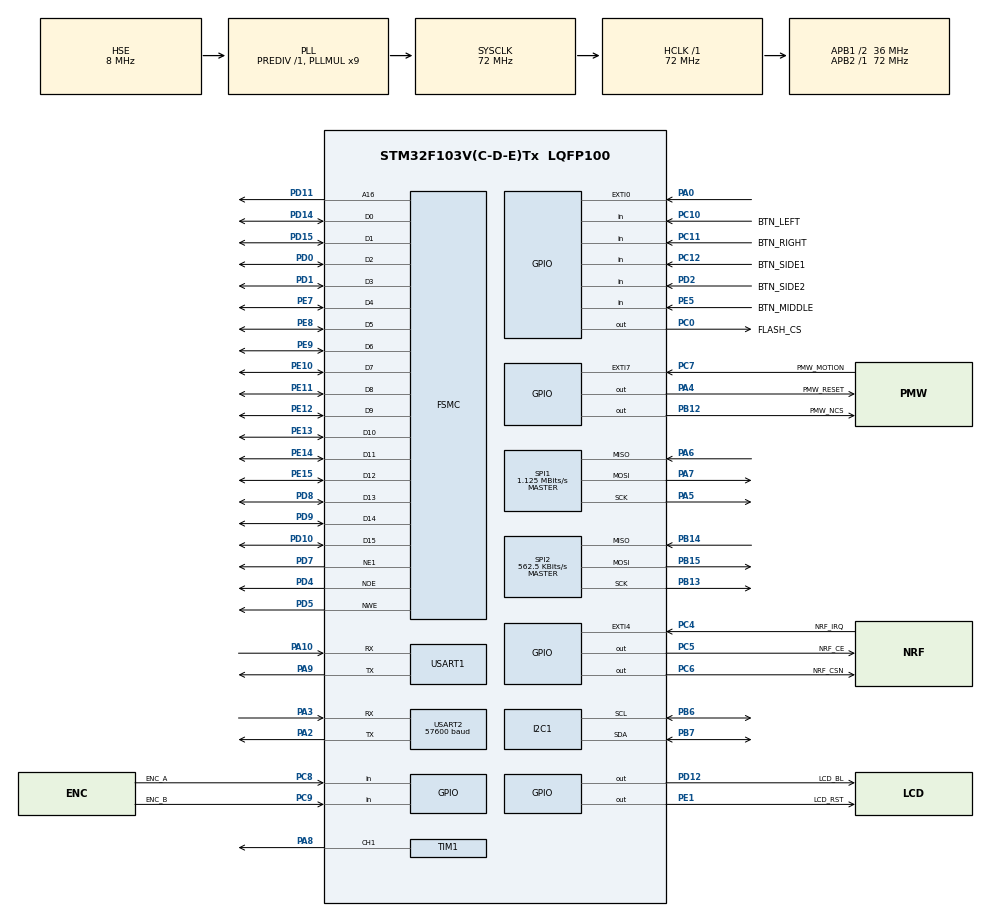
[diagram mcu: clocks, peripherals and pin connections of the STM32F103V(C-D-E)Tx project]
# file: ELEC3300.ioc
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Dma.Request0=TIM1_CH1
Dma.TIM1_CH1.0.Direction=DMA_MEMORY_TO_PERIPH
Dma.TIM1_CH1.0.Instance=DMA1_Channel2
Dma.TIM1_CH1.0.MemDataAlignment=DMA_MDATAALIGN_HALFWORD
Dma.TIM1_CH1.0.MemInc=DMA_MINC_ENABLE
Dma.TIM1_CH1.0.Mode=DMA_NORMAL
Dma.TIM1_CH1.0.PeriphDataAlignment=DMA_PDATAALIGN_HALFWORD
Dma.TIM1_CH1.0.PeriphInc=DMA_PINC_DISABLE
Dma.TIM1_CH1.0.Priority=DMA_PRIORITY_HIGH
FREERTOS.Tasks01=defaultTask,24,256,StartDefaultTask,Default,NULL,Dynamic,NULL,NULL
FREERTOS.configTOTAL_HEAP_SIZE=16384
Mcu.Family=STM32F1
Mcu.Name=STM32F103V(C-D-E)Tx
Mcu.Package=LQFP100
NVIC.DMA1_Channel2_IRQn=true\:5\:0\:false\:false\:true\:true\:false\:true\:true
NVIC.EXTI0_IRQn=true\:5\:0\:false\:false\:true\:true\:true\:true\:true
NVIC.EXTI4_IRQn=true\:5\:0\:false\:false\:true\:true\:true\:true\:true
NVIC.EXTI9_5_IRQn=true\:5\:0\:false\:false\:true\:true\:true\:true\:true
NVIC.PriorityGroup=NVIC_PRIORITYGROUP_4
NVIC.TIM4_IRQn=true\:15\:0\:false\:false\:true\:false\:false\:true\:true
NVIC.TimeBase=TIM4_IRQn
NVIC.TimeBaseIP=TIM4
OSC_IN.Mode=HSE-External-Oscillator
OSC_IN.Signal=RCC_OSC_IN
OSC_OUT.Mode=HSE-External-Oscillator
OSC_OUT.Signal=RCC_OSC_OUT
PA0-WKUP.Signal=GPXTI0
PA10.Mode=Asynchronous
PA10.Signal=USART1_RX
PA13.Mode=Serial_Wire
PA13.Signal=SYS_JTMS-SWDIO
PA14.Mode=Serial_Wire
PA14.Signal=SYS_JTCK-SWCLK
PA2.Mode=Asynchronous
PA2.Signal=USART2_TX
PA3.Mode=Asynchronous
PA3.Signal=USART2_RX
PA4.GPIO_Label=PMW_RESET
PA4.PinState=GPIO_PIN_SET
PA4.Signal=GPIO_Output
PA5.Mode=Full_Duplex_Master
PA5.Signal=SPI1_SCK
PA6.Mode=Full_Duplex_Master
PA6.Signal=SPI1_MISO
PA7.Mode=Full_Duplex_Master
PA7.Signal=SPI1_MOSI
PA8.GPIO_Speed=GPIO_SPEED_FREQ_HIGH
PA8.Signal=S_TIM1_CH1
PA9.Mode=Asynchronous
PA9.Signal=USART1_TX
PB12.GPIO_Label=PMW_NCS
PB12.PinState=GPIO_PIN_SET
PB12.Signal=GPIO_Output
PB13.Mode=Full_Duplex_Master
PB13.Signal=SPI2_SCK
PB14.Mode=Full_Duplex_Master
PB14.Signal=SPI2_MISO
PB15.Mode=Full_Duplex_Master
PB15.Signal=SPI2_MOSI
PB6.Mode=I2C
PB6.Signal=I2C1_SCL
PB7.Mode=I2C
PB7.Signal=I2C1_SDA
PC0.GPIO_Label=FLASH_CS
PC0.PinState=GPIO_PIN_SET
PC0.Signal=GPIO_Output
PC10.GPIO_Label=BTN_LEFT
PC10.GPIO_PuPd=GPIO_PULLUP
PC10.Signal=GPIO_Input
PC11.GPIO_Label=BTN_RIGHT
PC11.GPIO_PuPd=GPIO_PULLUP
PC11.Signal=GPIO_Input
PC12.GPIO_Label=BTN_SIDE1
PC12.GPIO_PuPd=GPIO_PULLUP
PC12.Signal=GPIO_Input
PC4.GPIO_Label=NRF_IRQ
PC4.GPIO_ModeDefaultEXTI=GPIO_MODE_IT_FALLING
PC4.GPIO_PuPd=GPIO_PULLUP
PC4.Signal=GPXTI4
PC5.GPIO_Label=NRF_CE
PC5.Signal=GPIO_Output
PC6.GPIO_Label=NRF_CSN
PC6.PinState=GPIO_PIN_SET
PC6.Signal=GPIO_Output
PC7.GPIO_Label=PMW_MOTION
PC7.GPIO_ModeDefaultEXTI=GPIO_MODE_IT_FALLING
PC7.GPIO_PuPd=GPIO_PULLUP
PC7.Signal=GPXTI7
PC8.GPIO_Label=ENC_A
PC8.GPIO_PuPd=GPIO_PULLUP
PC8.Signal=GPIO_Input
PC9.GPIO_Label=ENC_B
PC9.GPIO_PuPd=GPIO_PULLUP
PC9.Signal=GPIO_Input
PD0.Mode=16b-d1
PD0.Signal=FSMC_D2
PD1.Mode=16b-d1
PD1.Signal=FSMC_D3
PD10.Mode=16b-d1
PD10.Signal=FSMC_D15
PD11.Mode=A16_1
PD11.Signal=FSMC_A16
PD12.GPIO_Label=LCD_BL
PD12.GPIO_Speed=GPIO_SPEED_FREQ_HIGH
PD12.PinState=GPIO_PIN_RESET
PD12.Signal=GPIO_Output
PD14.Mode=16b-d1
PD14.Signal=FSMC_D0
PD15.Mode=16b-d1
PD15.Signal=FSMC_D1
PD2.GPIO_Label=BTN_SIDE2
PD2.GPIO_PuPd=GPIO_PULLUP
PD2.Signal=GPIO_Input
PD4.Mode=Lcd1
PD4.Signal=FSMC_NOE
PD5.Mode=Lcd1
PD5.Signal=FSMC_NWE
PD7.Mode=NorPsramChipSelect1_1
PD7.Signal=FSMC_NE1
PD8.Mode=16b-d1
PD8.Signal=FSMC_D13
PD9.Mode=16b-d1
PD9.Signal=FSMC_D14
PE1.GPIO_Label=LCD_RST
PE1.GPIO_Speed=GPIO_SPEED_FREQ_HIGH
PE1.PinState=GPIO_PIN_RESET
PE1.Signal=GPIO_Output
PE10.Mode=16b-d1
PE10.Signal=FSMC_D7
PE11.Mode=16b-d1
PE11.Signal=FSMC_D8
PE12.Mode=16b-d1
PE12.Signal=FSMC_D9
PE13.Mode=16b-d1
PE13.Signal=FSMC_D10
PE14.Mode=16b-d1
PE14.Signal=FSMC_D11
PE15.Mode=16b-d1
PE15.Signal=FSMC_D12
PE5.GPIO_Label=BTN_MIDDLE
PE5.GPIO_PuPd=GPIO_PULLUP
PE5.Signal=GPIO_Input
PE7.Mode=16b-d1
PE7.Signal=FSMC_D4
PE8.Mode=16b-d1
PE8.Signal=FSMC_D5
PE9.Mode=16b-d1
PE9.Signal=FSMC_D6
ProjectManager.HeapSize=0x200
ProjectManager.StackSize=0x400
ProjectManager.TargetToolchain=CMake
RCC.AHBFreq_Value=72000000
RCC.APB1CLKDivider=RCC_HCLK_DIV2
RCC.APB1Freq_Value=36000000
RCC.APB1TimFreq_Value=72000000
RCC.APB2Freq_Value=72000000
RCC.APB2TimFreq_Value=72000000
RCC.HCLKFreq_Value=72000000
RCC.PLLMUL=RCC_PLL_MUL9
RCC.PLLSourceVirtual=RCC_PLLSOURCE_HSE
RCC.SYSCLKFreq_VALUE=72000000
RCC.SYSCLKSource=RCC_SYSCLKSOURCE_PLLCLK
RCC.USBFreq_Value=72000000
SH.S_TIM1_CH1.0=TIM1_CH1,PWM Generation1 CH1
SPI1.BaudRatePrescaler=SPI_BAUDRATEPRESCALER_64
SPI1.CalculateBaudRate=1.125 MBits/s
SPI1.Direction=SPI_DIRECTION_2LINES
SPI1.Mode=SPI_MODE_MASTER
SPI1.VirtualType=VM_MASTER
SPI2.BaudRatePrescaler=SPI_BAUDRATEPRESCALER_64
SPI2.CLKPhase=SPI_PHASE_2EDGE
SPI2.CLKPolarity=SPI_POLARITY_HIGH
SPI2.CalculateBaudRate=562.5 KBits/s
SPI2.Direction=SPI_DIRECTION_2LINES
SPI2.Mode=SPI_MODE_MASTER
SPI2.VirtualType=VM_MASTER
TIM1.Channel-PWM\ Generation1\ CH1=TIM_CHANNEL_1
TIM1.Period=89
USART1.VirtualMode=VM_ASYNC
USART2.BaudRate=57600
USART2.VirtualMode=VM_ASYNC
VP_FREERTOS_VS_CMSIS_V2.Mode=CMSIS_V2
VP_SYS_VS_tim4.Mode=TIM4
VP_TIM1_VS_ClockSourceINT.Mode=Internal
board=custom

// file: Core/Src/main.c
/* USER CODE BEGIN Header */
/**
  ******************************************************************************
  * @file           : main.c
  * @brief          : Main program body
  ******************************************************************************
  * @attention
  *
  * Copyright (c) 2026 STMicroelectronics.
  * All rights reserved.
  *
  * This software is licensed under terms that can be found in the LICENSE file
  * in the root directory of this software component.
  * If no LICENSE file comes with this software, it is provided AS-IS.
  *
  ******************************************************************************
  */
/* USER CODE END Header */
#include "main.h"
#include "cmsis_os.h"

/* USER CODE BEGIN Includes */
#include "lcd.h"
#include "pmw3360_test.h"
/* USER CODE END Includes */

I2C_HandleTypeDef hi2c1;

SPI_HandleTypeDef hspi1;
SPI_HandleTypeDef hspi2;

TIM_HandleTypeDef htim1;
DMA_HandleTypeDef hdma_tim1_ch1;

UART_HandleTypeDef huart1;
UART_HandleTypeDef huart2;

SRAM_HandleTypeDef hsram1;

/* Definitions for defaultTask */
osThreadId_t defaultTaskHandle;
const osThreadAttr_t defaultTask_attributes = {
  .name = "defaultTask",
  .stack_size = 256 * 4,
  .priority = (osPriority_t) osPriorityNormal,
};

void SystemClock_Config(void);
static void MX_GPIO_Init(void);
static void MX_DMA_Init(void);
static void MX_I2C1_Init(void);
static void MX_SPI1_Init(void);
static void MX_SPI2_Init(void);
static void MX_USART1_UART_Init(void);
static void MX_USART2_UART_Init(void);
static void MX_FSMC_Init(void);
static void MX_TIM1_Init(void);
void StartDefaultTask(void *argument);

int main(void)
{

  /* MCU Configuration--------------------------------------------------------*/

  /* Reset of all peripherals, Initializes the Flash interface and the Systick. */
  HAL_Init();

  /* Configure the system clock */
  SystemClock_Config();

  /* Initialize all configured peripherals */
  MX_GPIO_Init();
  MX_DMA_Init();
  MX_I2C1_Init();
  MX_SPI1_Init();
  MX_SPI2_Init();
  MX_USART1_UART_Init();
  MX_USART2_UART_Init();
  MX_FSMC_Init();
  MX_TIM1_Init();
  /* USER CODE BEGIN 2 */
  LCD_INIT();
  LCD_DrawString(0, 0, "PMW3360 motion test");
  /* USER CODE END 2 */

  /* Init scheduler */
  osKernelInitialize();

  /* Create the thread(s) */
  /* creation of defaultTask */
  defaultTaskHandle = osThreadNew(StartDefaultTask, NULL, &defaultTask_attributes);

  /* Start scheduler */
  osKernelStart();

  /* We should never get here as control is now taken by the scheduler */

  /* Infinite loop */
  while (1)
  {

  }
}

void SystemClock_Config(void)
{
  RCC_OscInitTypeDef RCC_OscInitStruct = {0};
  RCC_ClkInitTypeDef RCC_ClkInitStruct = {0};

  /** Initializes the RCC Oscillators according to the specified parameters
  * in the RCC_OscInitTypeDef structure.
  */
  RCC_OscInitStruct.OscillatorType = RCC_OSCILLATORTYPE_HSE;
  RCC_OscInitStruct.HSEState = RCC_HSE_ON;
  RCC_OscInitStruct.HSEPredivValue = RCC_HSE_PREDIV_DIV1;
  RCC_OscInitStruct.HSIState = RCC_HSI_ON;
  RCC_OscInitStruct.PLL.PLLState = RCC_PLL_ON;
  RCC_OscInitStruct.PLL.PLLSource = RCC_PLLSOURCE_HSE;
  RCC_OscInitStruct.PLL.PLLMUL = RCC_PLL_MUL9;
  if (HAL_RCC_OscConfig(&RCC_OscInitStruct) != HAL_OK)
  {
    Error_Handler();
  }

  /** Initializes the CPU, AHB and APB buses clocks
  */
  RCC_ClkInitStruct.ClockType = RCC_CLOCKTYPE_HCLK|RCC_CLOCKTYPE_SYSCLK
                              |RCC_CLOCKTYPE_PCLK1|RCC_CLOCKTYPE_PCLK2;
  RCC_ClkInitStruct.SYSCLKSource = RCC_SYSCLKSOURCE_PLLCLK;
  RCC_ClkInitStruct.AHBCLKDivider = RCC_SYSCLK_DIV1;
  RCC_ClkInitStruct.APB1CLKDivider = RCC_HCLK_DIV2;
  RCC_ClkInitStruct.APB2CLKDivider = RCC_HCLK_DIV1;

  if (HAL_RCC_ClockConfig(&RCC_ClkInitStruct, FLASH_LATENCY_2) != HAL_OK)
  {
    Error_Handler();
  }
}

static void MX_I2C1_Init(void)
{

  hi2c1.Instance = I2C1;
  hi2c1.Init.ClockSpeed = 100000;
  hi2c1.Init.DutyCycle = I2C_DUTYCYCLE_2;
  hi2c1.Init.OwnAddress1 = 0;
  hi2c1.Init.AddressingMode = I2C_ADDRESSINGMODE_7BIT;
  hi2c1.Init.DualAddressMode = I2C_DUALADDRESS_DISABLE;
  hi2c1.Init.OwnAddress2 = 0;
  hi2c1.Init.GeneralCallMode = I2C_GENERALCALL_DISABLE;
  hi2c1.Init.NoStretchMode = I2C_NOSTRETCH_DISABLE;
  if (HAL_I2C_Init(&hi2c1) != HAL_OK)
  {
    Error_Handler();
  }

}

static void MX_SPI1_Init(void)
{

  /* SPI1 parameter configuration*/
  hspi1.Instance = SPI1;
  hspi1.Init.Mode = SPI_MODE_MASTER;
  hspi1.Init.Direction = SPI_DIRECTION_2LINES;
  hspi1.Init.DataSize = SPI_DATASIZE_8BIT;
  hspi1.Init.CLKPolarity = SPI_POLARITY_LOW;
  hspi1.Init.CLKPhase = SPI_PHASE_1EDGE;
  hspi1.Init.NSS = SPI_NSS_SOFT;
  hspi1.Init.BaudRatePrescaler = SPI_BAUDRATEPRESCALER_64;
  hspi1.Init.FirstBit = SPI_FIRSTBIT_MSB;
  hspi1.Init.TIMode = SPI_TIMODE_DISABLE;
  hspi1.Init.CRCCalculation = SPI_CRCCALCULATION_DISABLE;
  hspi1.Init.CRCPolynomial = 10;
  if (HAL_SPI_Init(&hspi1) != HAL_OK)
  {
    Error_Handler();
  }

}

static void MX_SPI2_Init(void)
{

  /* SPI2 parameter configuration*/
  hspi2.Instance = SPI2;
  hspi2.Init.Mode = SPI_MODE_MASTER;
  hspi2.Init.Direction = SPI_DIRECTION_2LINES;
  hspi2.Init.DataSize = SPI_DATASIZE_8BIT;
  hspi2.Init.CLKPolarity = SPI_POLARITY_HIGH;
  hspi2.Init.CLKPhase = SPI_PHASE_2EDGE;
  hspi2.Init.NSS = SPI_NSS_SOFT;
  hspi2.Init.BaudRatePrescaler = SPI_BAUDRATEPRESCALER_64;
  hspi2.Init.FirstBit = SPI_FIRSTBIT_MSB;
  hspi2.Init.TIMode = SPI_TIMODE_DISABLE;
  hspi2.Init.CRCCalculation = SPI_CRCCALCULATION_DISABLE;
  hspi2.Init.CRCPolynomial = 10;
  if (HAL_SPI_Init(&hspi2) != HAL_OK)
  {
    Error_Handler();
  }

}

static void MX_TIM1_Init(void)
{

  TIM_ClockConfigTypeDef sClockSourceConfig = {0};
  TIM_MasterConfigTypeDef sMasterConfig = {0};
  TIM_OC_InitTypeDef sConfigOC = {0};
  TIM_BreakDeadTimeConfigTypeDef sBreakDeadTimeConfig = {0};

  htim1.Instance = TIM1;
  htim1.Init.Prescaler = 0;
  htim1.Init.CounterMode = TIM_COUNTERMODE_UP;
  htim1.Init.Period = 89;
  htim1.Init.ClockDivision = TIM_CLOCKDIVISION_DIV1;
  htim1.Init.RepetitionCounter = 0;
  htim1.Init.AutoReloadPreload = TIM_AUTORELOAD_PRELOAD_DISABLE;
  if (HAL_TIM_Base_Init(&htim1) != HAL_OK)
  {
    Error_Handler();
  }
  sClockSourceConfig.ClockSource = TIM_CLOCKSOURCE_INTERNAL;
  if (HAL_TIM_ConfigClockSource(&htim1, &sClockSourceConfig) != HAL_OK)
  {
    Error_Handler();
  }
  if (HAL_TIM_PWM_Init(&htim1) != HAL_OK)
  {
    Error_Handler();
  }
  sMasterConfig.MasterOutputTrigger = TIM_TRGO_RESET;
  sMasterConfig.MasterSlaveMode = TIM_MASTERSLAVEMODE_DISABLE;
  if (HAL_TIMEx_MasterConfigSynchronization(&htim1, &sMasterConfig) != HAL_OK)
  {
    Error_Handler();
  }
  sConfigOC.OCMode = TIM_OCMODE_PWM1;
  sConfigOC.Pulse = 0;
  sConfigOC.OCPolarity = TIM_OCPOLARITY_HIGH;
  sConfigOC.OCNPolarity = TIM_OCNPOLARITY_HIGH;
  sConfigOC.OCFastMode = TIM_OCFAST_DISABLE;
  sConfigOC.OCIdleState = TIM_OCIDLESTATE_RESET;
  sConfigOC.OCNIdleState = TIM_OCNIDLESTATE_RESET;
  if (HAL_TIM_PWM_ConfigChannel(&htim1, &sConfigOC, TIM_CHANNEL_1) != HAL_OK)
  {
    Error_Handler();
  }
  sBreakDeadTimeConfig.OffStateRunMode = TIM_OSSR_DISABLE;
  sBreakDeadTimeConfig.OffStateIDLEMode = TIM_OSSI_DISABLE;
  sBreakDeadTimeConfig.LockLevel = TIM_LOCKLEVEL_OFF;
  sBreakDeadTimeConfig.DeadTime = 0;
  sBreakDeadTimeConfig.BreakState = TIM_BREAK_DISABLE;
  sBreakDeadTimeConfig.BreakPolarity = TIM_BREAKPOLARITY_HIGH;
  sBreakDeadTimeConfig.AutomaticOutput = TIM_AUTOMATICOUTPUT_DISABLE;
  if (HAL_TIMEx_ConfigBreakDeadTime(&htim1, &sBreakDeadTimeConfig) != HAL_OK)
  {
    Error_Handler();
  }
  HAL_TIM_MspPostInit(&htim1);

}

static void MX_USART1_UART_Init(void)
{

  huart1.Instance = USART1;
  huart1.Init.BaudRate = 115200;
  huart1.Init.WordLength = UART_WORDLENGTH_8B;
  huart1.Init.StopBits = UART_STOPBITS_1;
  huart1.Init.Parity = UART_PARITY_NONE;
  huart1.Init.Mode = UART_MODE_TX_RX;
  huart1.Init.HwFlowCtl = UART_HWCONTROL_NONE;
  huart1.Init.OverSampling = UART_OVERSAMPLING_16;
  if (HAL_UART_Init(&huart1) != HAL_OK)
  {
    Error_Handler();
  }

}

static void MX_USART2_UART_Init(void)
{

  huart2.Instance = USART2;
  huart2.Init.BaudRate = 57600;
  huart2.Init.WordLength = UART_WORDLENGTH_8B;
  huart2.Init.StopBits = UART_STOPBITS_1;
  huart2.Init.Parity = UART_PARITY_NONE;
  huart2.Init.Mode = UART_MODE_TX_RX;
  huart2.Init.HwFlowCtl = UART_HWCONTROL_NONE;
  huart2.Init.OverSampling = UART_OVERSAMPLING_16;
  if (HAL_UART_Init(&huart2) != HAL_OK)
  {
    Error_Handler();
  }

}

static void MX_DMA_Init(void)
{

  /* DMA controller clock enable */
  __HAL_RCC_DMA1_CLK_ENABLE();

  /* DMA interrupt init */
  /* DMA1_Channel2_IRQn interrupt configuration */
  HAL_NVIC_SetPriority(DMA1_Channel2_IRQn, 5, 0);
  HAL_NVIC_EnableIRQ(DMA1_Channel2_IRQn);

}

static void MX_GPIO_Init(void)
{
  GPIO_InitTypeDef GPIO_InitStruct = {0};

  /* GPIO Ports Clock Enable */
  __HAL_RCC_GPIOE_CLK_ENABLE();
  __HAL_RCC_GPIOC_CLK_ENABLE();
  __HAL_RCC_GPIOA_CLK_ENABLE();
  __HAL_RCC_GPIOB_CLK_ENABLE();
  __HAL_RCC_GPIOD_CLK_ENABLE();

  /*Configure GPIO pin Output Level */
  HAL_GPIO_WritePin(GPIOC, FLASH_CS_Pin|NRF_CSN_Pin, GPIO_PIN_SET);

  /*Configure GPIO pin Output Level */
  HAL_GPIO_WritePin(PMW_RESET_GPIO_Port, PMW_RESET_Pin, GPIO_PIN_SET);

  /*Configure GPIO pin Output Level */
  HAL_GPIO_WritePin(NRF_CE_GPIO_Port, NRF_CE_Pin, GPIO_PIN_RESET);

  /*Configure GPIO pin Output Level */
  HAL_GPIO_WritePin(PMW_NCS_GPIO_Port, PMW_NCS_Pin, GPIO_PIN_SET);

  /*Configure GPIO pin Output Level */
  HAL_GPIO_WritePin(LCD_BL_GPIO_Port, LCD_BL_Pin, GPIO_PIN_RESET);

  /*Configure GPIO pin Output Level */
  HAL_GPIO_WritePin(LCD_RST_GPIO_Port, LCD_RST_Pin, GPIO_PIN_RESET);

  /*Configure GPIO pin : BTN_MIDDLE_Pin */
  GPIO_InitStruct.Pin = BTN_MIDDLE_Pin;
  GPIO_InitStruct.Mode = GPIO_MODE_INPUT;
  GPIO_InitStruct.Pull = GPIO_PULLUP;
  HAL_GPIO_Init(BTN_MIDDLE_GPIO_Port, &GPIO_InitStruct);

  /*Configure GPIO pins : FLASH_CS_Pin NRF_CE_Pin NRF_CSN_Pin */
  GPIO_InitStruct.Pin = FLASH_CS_Pin|NRF_CE_Pin|NRF_CSN_Pin;
  GPIO_InitStruct.Mode = GPIO_MODE_OUTPUT_PP;
  GPIO_InitStruct.Pull = GPIO_NOPULL;
  GPIO_InitStruct.Speed = GPIO_SPEED_FREQ_LOW;
  HAL_GPIO_Init(GPIOC, &GPIO_InitStruct);

  /*Configure GPIO pin : PA0 */
  GPIO_InitStruct.Pin = GPIO_PIN_0;
  GPIO_InitStruct.Mode = GPIO_MODE_IT_RISING;
  GPIO_InitStruct.Pull = GPIO_NOPULL;
  HAL_GPIO_Init(GPIOA, &GPIO_InitStruct);

  /*Configure GPIO pin : PMW_RESET_Pin */
  GPIO_InitStruct.Pin = PMW_RESET_Pin;
  GPIO_InitStruct.Mode = GPIO_MODE_OUTPUT_PP;
  GPIO_InitStruct.Pull = GPIO_NOPULL;
  GPIO_InitStruct.Speed = GPIO_SPEED_FREQ_LOW;
  HAL_GPIO_Init(PMW_RESET_GPIO_Port, &GPIO_InitStruct);

  /*Configure GPIO pins : NRF_IRQ_Pin PMW_MOTION_Pin */
  GPIO_InitStruct.Pin = NRF_IRQ_Pin|PMW_MOTION_Pin;
  GPIO_InitStruct.Mode = GPIO_MODE_IT_FALLING;
  GPIO_InitStruct.Pull = GPIO_PULLUP;
  HAL_GPIO_Init(GPIOC, &GPIO_InitStruct);

  /*Configure GPIO pin : PMW_NCS_Pin */
  GPIO_InitStruct.Pin = PMW_NCS_Pin;
  GPIO_InitStruct.Mode = GPIO_MODE_OUTPUT_PP;
  GPIO_InitStruct.Pull = GPIO_NOPULL;
  GPIO_InitStruct.Speed = GPIO_SPEED_FREQ_LOW;
  HAL_GPIO_Init(PMW_NCS_GPIO_Port, &GPIO_InitStruct);

  /*Configure GPIO pin : LCD_BL_Pin */
  GPIO_InitStruct.Pin = LCD_BL_Pin;
  GPIO_InitStruct.Mode = GPIO_MODE_OUTPUT_PP;
  GPIO_InitStruct.Pull = GPIO_NOPULL;
  GPIO_InitStruct.Speed = GPIO_SPEED_FREQ_HIGH;
  HAL_GPIO_Init(LCD_BL_GPIO_Port, &GPIO_InitStruct);

  /*Configure GPIO pins : ENC_A_Pin ENC_B_Pin BTN_LEFT_Pin BTN_RIGHT_Pin
                           BTN_SIDE1_Pin */
  GPIO_InitStruct.Pin = ENC_A_Pin|ENC_B_Pin|BTN_LEFT_Pin|BTN_RIGHT_Pin
                          |BTN_SIDE1_Pin;
  GPIO_InitStruct.Mode = GPIO_MODE_INPUT;
  GPIO_InitStruct.Pull = GPIO_PULLUP;
  HAL_GPIO_Init(GPIOC, &GPIO_InitStruct);

  /*Configure GPIO pin : BTN_SIDE2_Pin */
  GPIO_InitStruct.Pin = BTN_SIDE2_Pin;
  GPIO_InitStruct.Mode = GPIO_MODE_INPUT;
  GPIO_InitStruct.Pull = GPIO_PULLUP;
  HAL_GPIO_Init(BTN_SIDE2_GPIO_Port, &GPIO_InitStruct);

  /*Configure GPIO pin : LCD_RST_Pin */
  GPIO_InitStruct.Pin = LCD_RST_Pin;
  GPIO_InitStruct.Mode = GPIO_MODE_OUTPUT_PP;
  GPIO_InitStruct.Pull = GPIO_NOPULL;
  GPIO_InitStruct.Speed = GPIO_SPEED_FREQ_HIGH;
  HAL_GPIO_Init(LCD_RST_GPIO_Port, &GPIO_InitStruct);

  /* EXTI interrupt init*/
  HAL_NVIC_SetPriority(EXTI0_IRQn, 5, 0);
  HAL_NVIC_EnableIRQ(EXTI0_IRQn);

  HAL_NVIC_SetPriority(EXTI4_IRQn, 5, 0);
  HAL_NVIC_EnableIRQ(EXTI4_IRQn);

  HAL_NVIC_SetPriority(EXTI9_5_IRQn, 5, 0);
  HAL_NVIC_EnableIRQ(EXTI9_5_IRQn);

}

/* FSMC initialization function */
static void MX_FSMC_Init(void)
{

  FSMC_NORSRAM_TimingTypeDef Timing = {0};

  /** Perform the SRAM1 memory initialization sequence
  */
  hsram1.Instance = FSMC_NORSRAM_DEVICE;
  hsram1.Extended = FSMC_NORSRAM_EXTENDED_DEVICE;
  /* hsram1.Init */
  hsram1.Init.NSBank = FSMC_NORSRAM_BANK1;
  hsram1.Init.DataAddressMux = FSMC_DATA_ADDRESS_MUX_DISABLE;
  hsram1.Init.MemoryType = FSMC_MEMORY_TYPE_SRAM;
  hsram1.Init.MemoryDataWidth = FSMC_NORSRAM_MEM_BUS_WIDTH_16;
  hsram1.Init.BurstAccessMode = FSMC_BURST_ACCESS_MODE_DISABLE;
  hsram1.Init.WaitSignalPolarity = FSMC_WAIT_SIGNAL_POLARITY_LOW;
  hsram1.Init.WrapMode = FSMC_WRAP_MODE_DISABLE;
  hsram1.Init.WaitSignalActive = FSMC_WAIT_TIMING_BEFORE_WS;
  hsram1.Init.WriteOperation = FSMC_WRITE_OPERATION_ENABLE;
  hsram1.Init.WaitSignal = FSMC_WAIT_SIGNAL_DISABLE;
  hsram1.Init.ExtendedMode = FSMC_EXTENDED_MODE_DISABLE;
  hsram1.Init.AsynchronousWait = FSMC_ASYNCHRONOUS_WAIT_DISABLE;
  hsram1.Init.WriteBurst = FSMC_WRITE_BURST_DISABLE;
  /* Timing */
  Timing.AddressSetupTime = 15;
  Timing.AddressHoldTime = 15;
  Timing.DataSetupTime = 255;
  Timing.BusTurnAroundDuration = 15;
  Timing.CLKDivision = 16;
  Timing.DataLatency = 17;
  Timing.AccessMode = FSMC_ACCESS_MODE_A;
  /* ExtTiming */

  if (HAL_SRAM_Init(&hsram1, &Timing, NULL) != HAL_OK)
  {
    Error_Handler( );
  }

  /** Disconnect NADV
  */

  __HAL_AFIO_FSMCNADV_DISCONNECTED();

}

void StartDefaultTask(void *argument)
{
  /* USER CODE BEGIN 5 */
  PMW3360_Test_Init(&hspi2, &huart1);
  /* Infinite loop */
  for(;;)
  {
    PMW3360_Test_Poll();
    osDelay(10);
  }
  /* USER CODE END 5 */
}

void HAL_TIM_PeriodElapsedCallback(TIM_HandleTypeDef *htim)
{
  if (htim->Instance == TIM4)
  {
    HAL_IncTick();
  }
}

void Error_Handler(void)
{
  __disable_irq();
  while (1)
  {
  }
}
